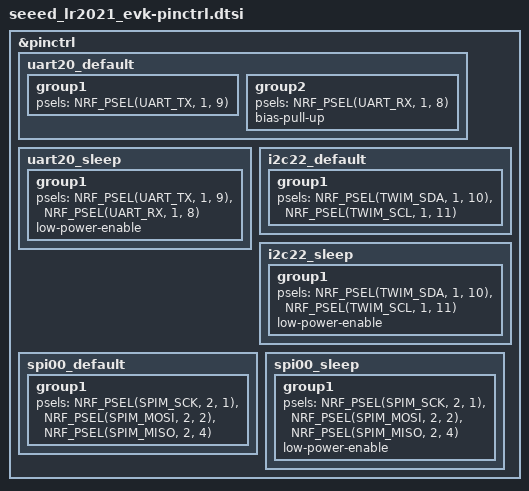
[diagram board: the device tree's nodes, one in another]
/*
 * Semtech LR2021 LoRa Plus EVK — pin control
 * Copyright (c) 2026 ZephCore
 * SPDX-License-Identifier: MIT
 *
 * Pin assignments are the XIAO nRF54L15's fixed connector mapping, copied from
 * Zephyr's xiao_nrf54l15-pinctrl.dtsi. Only the three buses this kit actually
 * uses are declared:
 *
 *   uart20  P1.09 TX / P1.08 RX  — console, via the SAMD11 CMSIS-DAP bridge
 *   i2c22   P1.10 SDA / P1.11 SCL — D4/D5: OLED + the two I2C Grove ports
 *   spi00   P2.01 SCK / P2.02 MOSI / P2.04 MISO — D8/D10/D9: LR2021
 *
 * uart21 (D6/D7) is deliberately absent — see the DIO7/DIO11 note in the .dts.
 */

&pinctrl {
	/omit-if-no-ref/ uart20_default: uart20_default {
		group1 {
			psels = <NRF_PSEL(UART_TX, 1, 9)>;
		};

		group2 {
			psels = <NRF_PSEL(UART_RX, 1, 8)>;
			bias-pull-up;
		};
	};

	/omit-if-no-ref/ uart20_sleep: uart20_sleep {
		group1 {
			psels = <NRF_PSEL(UART_TX, 1, 9)>,
				<NRF_PSEL(UART_RX, 1, 8)>;
			low-power-enable;
		};
	};

	/omit-if-no-ref/ i2c22_default: i2c22_default {
		group1 {
			psels = <NRF_PSEL(TWIM_SDA, 1, 10)>,
				<NRF_PSEL(TWIM_SCL, 1, 11)>;
		};
	};

	/omit-if-no-ref/ i2c22_sleep: i2c22_sleep {
		group1 {
			psels = <NRF_PSEL(TWIM_SDA, 1, 10)>,
				<NRF_PSEL(TWIM_SCL, 1, 11)>;
			low-power-enable;
		};
	};

	/omit-if-no-ref/ spi00_default: spi00_default {
		group1 {
			psels = <NRF_PSEL(SPIM_SCK, 2, 1)>,
				<NRF_PSEL(SPIM_MOSI, 2, 2)>,
				<NRF_PSEL(SPIM_MISO, 2, 4)>;
		};
	};

	/omit-if-no-ref/ spi00_sleep: spi00_sleep {
		group1 {
			psels = <NRF_PSEL(SPIM_SCK, 2, 1)>,
				<NRF_PSEL(SPIM_MOSI, 2, 2)>,
				<NRF_PSEL(SPIM_MISO, 2, 4)>;
			low-power-enable;
		};
	};
};
